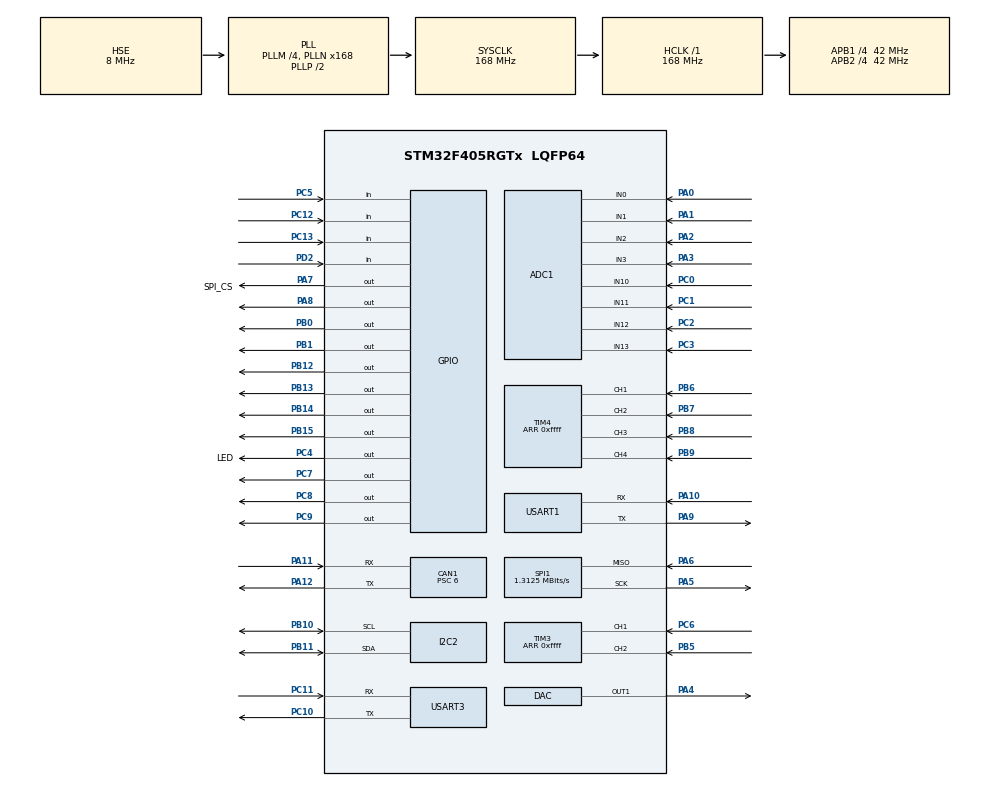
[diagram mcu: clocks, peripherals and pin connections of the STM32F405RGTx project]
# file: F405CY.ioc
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ADC1.Channel-0\#ChannelRegularConversion=ADC_CHANNEL_10
ADC1.Channel-1\#ChannelRegularConversion=ADC_CHANNEL_11
ADC1.Channel-2\#ChannelRegularConversion=ADC_CHANNEL_12
ADC1.Channel-3\#ChannelRegularConversion=ADC_CHANNEL_13
ADC1.Channel-4\#ChannelRegularConversion=ADC_CHANNEL_0
ADC1.Channel-5\#ChannelRegularConversion=ADC_CHANNEL_1
ADC1.Channel-6\#ChannelRegularConversion=ADC_CHANNEL_2
ADC1.Channel-7\#ChannelRegularConversion=ADC_CHANNEL_3
ADC1.DMAContinuousRequests=ENABLE
ADC1.ExternalTrigConv=ADC_EXTERNALTRIGCONV_T2_TRGO
ADC1.NbrOfConversion=8
ADC1.NbrOfConversionFlag=1
ADC1.Rank-0\#ChannelRegularConversion=1
ADC1.Rank-1\#ChannelRegularConversion=2
ADC1.Rank-2\#ChannelRegularConversion=3
ADC1.Rank-3\#ChannelRegularConversion=4
ADC1.Rank-4\#ChannelRegularConversion=5
ADC1.Rank-5\#ChannelRegularConversion=6
ADC1.Rank-6\#ChannelRegularConversion=7
ADC1.Rank-7\#ChannelRegularConversion=8
ADC1.SamplingTime-0\#ChannelRegularConversion=ADC_SAMPLETIME_3CYCLES
ADC1.SamplingTime-1\#ChannelRegularConversion=ADC_SAMPLETIME_3CYCLES
ADC1.SamplingTime-2\#ChannelRegularConversion=ADC_SAMPLETIME_3CYCLES
ADC1.SamplingTime-3\#ChannelRegularConversion=ADC_SAMPLETIME_3CYCLES
ADC1.SamplingTime-4\#ChannelRegularConversion=ADC_SAMPLETIME_3CYCLES
ADC1.SamplingTime-5\#ChannelRegularConversion=ADC_SAMPLETIME_3CYCLES
ADC1.SamplingTime-6\#ChannelRegularConversion=ADC_SAMPLETIME_3CYCLES
ADC1.SamplingTime-7\#ChannelRegularConversion=ADC_SAMPLETIME_3CYCLES
ADC1.ScanConvMode=ENABLE
ADC1.master=1
CAN1.BS1=CAN_BS1_7TQ
CAN1.BS2=CAN_BS2_6TQ
CAN1.CalculateTimeQuantum=142.85714285714286
CAN1.Prescaler=6
Dma.ADC1.2.Direction=DMA_PERIPH_TO_MEMORY
Dma.ADC1.2.FIFOMode=DMA_FIFOMODE_DISABLE
Dma.ADC1.2.Instance=DMA2_Stream0
Dma.ADC1.2.MemDataAlignment=DMA_MDATAALIGN_HALFWORD
Dma.ADC1.2.MemInc=DMA_MINC_ENABLE
Dma.ADC1.2.Mode=DMA_CIRCULAR
Dma.ADC1.2.PeriphDataAlignment=DMA_PDATAALIGN_HALFWORD
Dma.ADC1.2.PeriphInc=DMA_PINC_DISABLE
Dma.ADC1.2.Priority=DMA_PRIORITY_LOW
Dma.MEMTOMEM.3.Direction=DMA_MEMORY_TO_MEMORY
Dma.MEMTOMEM.3.FIFOMode=DMA_FIFOMODE_ENABLE
Dma.MEMTOMEM.3.FIFOThreshold=DMA_FIFO_THRESHOLD_FULL
Dma.MEMTOMEM.3.Instance=DMA2_Stream1
Dma.MEMTOMEM.3.MemBurst=DMA_MBURST_INC4
Dma.MEMTOMEM.3.MemDataAlignment=DMA_MDATAALIGN_HALFWORD
Dma.MEMTOMEM.3.MemInc=DMA_MINC_ENABLE
Dma.MEMTOMEM.3.Mode=DMA_NORMAL
Dma.MEMTOMEM.3.PeriphBurst=DMA_PBURST_INC4
Dma.MEMTOMEM.3.PeriphDataAlignment=DMA_PDATAALIGN_HALFWORD
Dma.MEMTOMEM.3.PeriphInc=DMA_PINC_ENABLE
Dma.MEMTOMEM.3.Priority=DMA_PRIORITY_LOW
Dma.Request0=USART1_RX
Dma.Request1=USART3_RX
Dma.Request2=ADC1
Dma.Request3=MEMTOMEM
Dma.USART1_RX.0.Direction=DMA_PERIPH_TO_MEMORY
Dma.USART1_RX.0.FIFOMode=DMA_FIFOMODE_DISABLE
Dma.USART1_RX.0.Instance=DMA2_Stream2
Dma.USART1_RX.0.MemDataAlignment=DMA_MDATAALIGN_BYTE
Dma.USART1_RX.0.MemInc=DMA_MINC_ENABLE
Dma.USART1_RX.0.Mode=DMA_NORMAL
Dma.USART1_RX.0.PeriphDataAlignment=DMA_PDATAALIGN_BYTE
Dma.USART1_RX.0.PeriphInc=DMA_PINC_DISABLE
Dma.USART1_RX.0.Priority=DMA_PRIORITY_LOW
Dma.USART3_RX.1.Direction=DMA_PERIPH_TO_MEMORY
Dma.USART3_RX.1.FIFOMode=DMA_FIFOMODE_DISABLE
Dma.USART3_RX.1.Instance=DMA1_Stream1
Dma.USART3_RX.1.MemDataAlignment=DMA_MDATAALIGN_BYTE
Dma.USART3_RX.1.MemInc=DMA_MINC_ENABLE
Dma.USART3_RX.1.Mode=DMA_NORMAL
Dma.USART3_RX.1.PeriphDataAlignment=DMA_PDATAALIGN_BYTE
Dma.USART3_RX.1.PeriphInc=DMA_PINC_DISABLE
Dma.USART3_RX.1.Priority=DMA_PRIORITY_LOW
FREERTOS.Queues01=canMsgQueue,16,CAN_MSG,0,Dynamic,NULL,NULL
FREERTOS.Tasks01=defaultTask,24,512,StartDefaultTask,As weak,NULL,Static,defaultTaskBuffer,defaultTaskControlBlock;usart1Task,8,512,StartUsart1Task,As weak,NULL,Static,usart1TaskBuffer,usart1TaskControlBlock;usart3Task,8,512,StartUsart3Task,As weak,NULL,Static,usart3TaskBuffer,usart3TaskControlBlock;adcTask,8,512,StartAdcTask,As weak,NULL,Static,adcTaskBuffer,adcTaskControlBlock;can1Task,8,512,StartCan1Task,As weak,NULL,Static,can1TaskBuffer,can1TaskControlBlock
I2C2.DutyCycle=I2C_DUTYCYCLE_16_9
I2C2.I2C_Mode=I2C_Fast
Mcu.Family=STM32F4
Mcu.Name=STM32F405RGTx
Mcu.Package=LQFP64
NVIC.CAN1_RX0_IRQn=true\:5\:0\:false\:false\:true\:true\:true\:true
NVIC.CAN1_RX1_IRQn=true\:5\:0\:false\:false\:true\:true\:true\:true
NVIC.DMA1_Stream1_IRQn=true\:5\:0\:false\:false\:true\:true\:false\:true
NVIC.DMA2_Stream0_IRQn=true\:5\:0\:false\:false\:true\:true\:false\:true
NVIC.DMA2_Stream1_IRQn=true\:5\:0\:false\:false\:true\:true\:true\:true
NVIC.DMA2_Stream2_IRQn=true\:5\:0\:false\:false\:true\:true\:false\:true
NVIC.PriorityGroup=NVIC_PRIORITYGROUP_4
NVIC.TIM1_UP_TIM10_IRQn=true\:0\:0\:false\:false\:true\:false\:false\:true
NVIC.TIM3_IRQn=true\:5\:0\:false\:false\:true\:true\:true\:true
NVIC.TIM4_IRQn=true\:5\:0\:false\:false\:true\:true\:true\:true
NVIC.TIM8_TRG_COM_TIM14_IRQn=true\:5\:0\:false\:false\:true\:true\:true\:true
NVIC.TimeBase=TIM1_UP_TIM10_IRQn
NVIC.TimeBaseIP=TIM1
NVIC.USART1_IRQn=true\:5\:0\:false\:false\:true\:true\:true\:true
NVIC.USART3_IRQn=true\:5\:0\:false\:false\:true\:true\:true\:true
PA0-WKUP.Signal=ADCx_IN0
PA1.Signal=ADCx_IN1
PA10.Mode=Asynchronous
PA10.Signal=USART1_RX
PA11.Mode=Master
PA11.Signal=CAN1_RX
PA12.Mode=Master
PA12.Signal=CAN1_TX
PA13.Mode=JTAG_5_pins
PA13.Signal=SYS_JTMS-SWDIO
PA14.Mode=JTAG_5_pins
PA14.Signal=SYS_JTCK-SWCLK
PA15.Mode=JTAG_5_pins
PA15.Signal=SYS_JTDI
PA2.Signal=ADCx_IN2
PA3.Signal=ADCx_IN3
PA4.Signal=COMP_DAC1_group
PA5.Mode=RX_Only_Simplex_Unidirect_Master
PA5.Signal=SPI1_SCK
PA6.Mode=RX_Only_Simplex_Unidirect_Master
PA6.Signal=SPI1_MISO
PA7.GPIO_Label=SPI_CS
PA7.PinState=GPIO_PIN_SET
PA7.Signal=GPIO_Output
PA8.Signal=GPIO_Output
PA9.Mode=Asynchronous
PA9.Signal=USART1_TX
PB0.Signal=GPIO_Output
PB1.Signal=GPIO_Output
PB10.Mode=I2C
PB10.Signal=I2C2_SCL
PB11.Mode=I2C
PB11.Signal=I2C2_SDA
PB12.GPIO_Speed=GPIO_SPEED_FREQ_HIGH
PB12.Signal=GPIO_Output
PB13.GPIO_Speed=GPIO_SPEED_FREQ_HIGH
PB13.Signal=GPIO_Output
PB14.GPIO_Speed=GPIO_SPEED_FREQ_HIGH
PB14.Signal=GPIO_Output
PB15.GPIO_Speed=GPIO_SPEED_FREQ_HIGH
PB15.Signal=GPIO_Output
PB3.Mode=JTAG_5_pins
PB3.Signal=SYS_JTDO-SWO
PB4.Mode=JTAG_5_pins
PB4.Signal=SYS_JTRST
PB5.GPIO_PuPd=GPIO_PULLUP
PB5.Signal=S_TIM3_CH2
PB6.GPIO_PuPd=GPIO_PULLUP
PB6.Signal=S_TIM4_CH1
PB7.GPIO_PuPd=GPIO_PULLUP
PB7.Signal=S_TIM4_CH2
PB8.GPIO_PuPd=GPIO_PULLUP
PB8.Signal=S_TIM4_CH3
PB9.GPIO_PuPd=GPIO_PULLUP
PB9.Signal=S_TIM4_CH4
PC0.Signal=ADCx_IN10
PC1.Signal=ADCx_IN11
PC10.Mode=Asynchronous
PC10.Signal=USART3_TX
PC11.Mode=Asynchronous
PC11.Signal=USART3_RX
PC12.GPIO_PuPd=GPIO_PULLUP
PC12.Signal=GPIO_Input
PC13-ANTI_TAMP.GPIO_PuPd=GPIO_PULLUP
PC13-ANTI_TAMP.Signal=GPIO_Input
PC14-OSC32_IN.Mode=LSE-External-Oscillator
PC14-OSC32_IN.Signal=RCC_OSC32_IN
PC15-OSC32_OUT.Mode=LSE-External-Oscillator
PC15-OSC32_OUT.Signal=RCC_OSC32_OUT
PC2.Signal=ADCx_IN12
PC3.Signal=ADCx_IN13
PC4.GPIO_Label=LED
PC4.GPIO_Speed=GPIO_SPEED_FREQ_HIGH
PC4.Signal=GPIO_Output
PC5.GPIO_PuPd=GPIO_PULLUP
PC5.Signal=GPIO_Input
PC6.GPIO_PuPd=GPIO_PULLUP
PC6.Signal=S_TIM3_CH1
PC7.GPIO_Speed=GPIO_SPEED_FREQ_HIGH
PC7.Signal=GPIO_Output
PC8.GPIO_Speed=GPIO_SPEED_FREQ_HIGH
PC8.Signal=GPIO_Output
PC9.GPIO_Speed=GPIO_SPEED_FREQ_HIGH
PC9.PinState=GPIO_PIN_RESET
PC9.Signal=GPIO_Output
PD2.GPIO_PuPd=GPIO_PULLUP
PD2.Signal=GPIO_Input
PH0-OSC_IN.Mode=HSE-External-Oscillator
PH0-OSC_IN.Signal=RCC_OSC_IN
PH1-OSC_OUT.Mode=HSE-External-Oscillator
PH1-OSC_OUT.Signal=RCC_OSC_OUT
ProjectManager.HeapSize=0x200
ProjectManager.StackSize=0x400
ProjectManager.TargetToolchain=STM32CubeIDE
RCC.48MHZClocksFreq_Value=84000000
RCC.AHBFreq_Value=168000000
RCC.APB1CLKDivider=RCC_HCLK_DIV4
RCC.APB1Freq_Value=42000000
RCC.APB1TimFreq_Value=84000000
RCC.APB2CLKDivider=RCC_HCLK_DIV4
RCC.APB2Freq_Value=42000000
RCC.APB2TimFreq_Value=84000000
RCC.CortexFreq_Value=168000000
RCC.HCLKFreq_Value=168000000
RCC.HSE_VALUE=8000000
RCC.HSI_VALUE=16000000
RCC.PLLM=4
RCC.PLLN=168
RCC.PLLSourceVirtual=RCC_PLLSOURCE_HSE
RCC.SYSCLKFreq_VALUE=168000000
RCC.SYSCLKSource=RCC_SYSCLKSOURCE_PLLCLK
RCC.VCOOutputFreq_Value=336000000
SH.ADCx_IN0.0=ADC1_IN0,IN0
SH.ADCx_IN1.0=ADC1_IN1,IN1
SH.ADCx_IN10.0=ADC1_IN10,IN10
SH.ADCx_IN11.0=ADC1_IN11,IN11
SH.ADCx_IN12.0=ADC1_IN12,IN12
SH.ADCx_IN13.0=ADC1_IN13,IN13
SH.ADCx_IN2.0=ADC1_IN2,IN2
SH.ADCx_IN3.0=ADC1_IN3,IN3
SH.COMP_DAC1_group.0=DAC_OUT1,DAC_OUT1
SH.S_TIM3_CH1.0=TIM3_CH1,Input_Capture1_from_TI1
SH.S_TIM3_CH2.0=TIM3_CH2,Input_Capture2_from_TI2
SH.S_TIM4_CH1.0=TIM4_CH1,Input_Capture1_from_TI1
SH.S_TIM4_CH2.0=TIM4_CH2,Input_Capture2_from_TI2
SH.S_TIM4_CH3.0=TIM4_CH3,Input_Capture3_from_TI3
SH.S_TIM4_CH4.0=TIM4_CH4,Input_Capture4_from_TI4
SPI1.BaudRatePrescaler=SPI_BAUDRATEPRESCALER_32
SPI1.CalculateBaudRate=1.3125 MBits/s
SPI1.DataSize=SPI_DATASIZE_16BIT
SPI1.Direction=SPI_DIRECTION_2LINES_RXONLY
SPI1.Mode=SPI_MODE_MASTER
SPI1.VirtualType=VM_MASTER
TIM14.AutoReloadPreload=TIM_AUTORELOAD_PRELOAD_ENABLE
TIM14.Period=999
TIM14.Prescaler=41
TIM2.AutoReloadPreload=TIM_AUTORELOAD_PRELOAD_ENABLE
TIM2.Period=524
TIM2.Prescaler=49
TIM2.TIM_MasterOutputTrigger=TIM_TRGO_UPDATE
TIM3.AutoReloadPreload=TIM_AUTORELOAD_PRELOAD_ENABLE
TIM3.Channel-Input_Capture1_from_TI1=TIM_CHANNEL_1
TIM3.Channel-Input_Capture2_from_TI2=TIM_CHANNEL_2
TIM3.ICPolarity_CH1=TIM_INPUTCHANNELPOLARITY_FALLING
TIM3.ICPolarity_CH2=TIM_INPUTCHANNELPOLARITY_FALLING
TIM3.Period=0xffff
TIM3.TIM_MasterOutputTrigger=TIM_TRGO_UPDATE
TIM4.AutoReloadPreload=TIM_AUTORELOAD_PRELOAD_ENABLE
TIM4.Channel-Input_Capture1_from_TI1=TIM_CHANNEL_1
TIM4.Channel-Input_Capture2_from_TI2=TIM_CHANNEL_2
TIM4.Channel-Input_Capture3_from_TI3=TIM_CHANNEL_3
TIM4.Channel-Input_Capture4_from_TI4=TIM_CHANNEL_4
TIM4.ICPolarity_CH1=TIM_INPUTCHANNELPOLARITY_FALLING
TIM4.ICPolarity_CH2=TIM_INPUTCHANNELPOLARITY_FALLING
TIM4.ICPolarity_CH3=TIM_INPUTCHANNELPOLARITY_FALLING
TIM4.ICPolarity_CH4=TIM_INPUTCHANNELPOLARITY_FALLING
TIM4.Period=0xffff
TIM4.TIM_MasterOutputTrigger=TIM_TRGO_UPDATE
USART1.VirtualMode=VM_ASYNC
USART3.VirtualMode=VM_ASYNC
VP_FREERTOS_VS_CMSIS_V2.Mode=CMSIS_V2
VP_SYS_VS_tim1.Mode=TIM1
VP_TIM14_VS_ClockSourceINT.Mode=Enable_Timer
VP_TIM2_VS_ClockSourceINT.Mode=Internal
board=custom

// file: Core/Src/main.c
/* USER CODE BEGIN Header */
/**
  ******************************************************************************
  * @file           : main.c
  * @brief          : Main program body
  ******************************************************************************
  * @attention
  *
  * <h2><center>&copy; Copyright (c) 2019 STMicroelectronics.
  * All rights reserved.</center></h2>
  *
  * This software component is licensed by ST under BSD 3-Clause license,
  * the "License"; You may not use this file except in compliance with the
  * License. You may obtain a copy of the License at:
  *                        opensource.org/licenses/BSD-3-Clause
  *
  ******************************************************************************
  */
/* USER CODE END Header */

#include "main.h"
#include "cmsis_os.h"
#include "adc.h"
#include "can.h"
#include "dac.h"
#include "dma.h"
#include "i2c.h"
#include "spi.h"
#include "tim.h"
#include "usart.h"
#include "gpio.h"

/* USER CODE BEGIN Includes */
#include "taskApp.h"

/* USER CODE END Includes */

void SystemClock_Config(void);
void MX_FREERTOS_Init(void);
/* USER CODE BEGIN PFP */
void init_led();
void InitMyApp();
void PorcKout();

/* USER CODE END PFP */

int main(void)
{

  /* MCU Configuration--------------------------------------------------------*/

  /* Reset of all peripherals, Initializes the Flash interface and the Systick. */
  HAL_Init();

  /* Configure the system clock */
  SystemClock_Config();

  /* Initialize all configured peripherals */
  MX_GPIO_Init();
  MX_DMA_Init();
  MX_USART1_UART_Init();
  MX_USART3_UART_Init();
  MX_ADC1_Init();
  MX_TIM2_Init();
  MX_CAN1_Init();
  MX_DAC_Init();
  MX_I2C2_Init();
  MX_SPI1_Init();
  MX_TIM3_Init();
  MX_TIM4_Init();
  MX_TIM14_Init();
  /* USER CODE BEGIN 2 */
  InitMyApp();
  /* USER CODE END 2 */
  /* Init scheduler */
  osKernelInitialize();

  /* Call init function for freertos objects (in freertos.c) */
  MX_FREERTOS_Init();

  /* Start scheduler */
  osKernelStart();

  /* We should never get here as control is now taken by the scheduler */

  /* Infinite loop */
  while (1)
  {

  }
}

void SystemClock_Config(void)
{
  RCC_OscInitTypeDef RCC_OscInitStruct = {0};
  RCC_ClkInitTypeDef RCC_ClkInitStruct = {0};

  /** Configure the main internal regulator output voltage
  */
  __HAL_RCC_PWR_CLK_ENABLE();
  __HAL_PWR_VOLTAGESCALING_CONFIG(PWR_REGULATOR_VOLTAGE_SCALE1);
  /** Initializes the CPU, AHB and APB busses clocks
  */
  RCC_OscInitStruct.OscillatorType = RCC_OSCILLATORTYPE_HSE;
  RCC_OscInitStruct.HSEState = RCC_HSE_ON;
  RCC_OscInitStruct.PLL.PLLState = RCC_PLL_ON;
  RCC_OscInitStruct.PLL.PLLSource = RCC_PLLSOURCE_HSE;
  RCC_OscInitStruct.PLL.PLLM = 4;
  RCC_OscInitStruct.PLL.PLLN = 168;
  RCC_OscInitStruct.PLL.PLLP = RCC_PLLP_DIV2;
  RCC_OscInitStruct.PLL.PLLQ = 4;
  if (HAL_RCC_OscConfig(&RCC_OscInitStruct) != HAL_OK)
  {
    Error_Handler();
  }
  /** Initializes the CPU, AHB and APB busses clocks
  */
  RCC_ClkInitStruct.ClockType = RCC_CLOCKTYPE_HCLK|RCC_CLOCKTYPE_SYSCLK
                              |RCC_CLOCKTYPE_PCLK1|RCC_CLOCKTYPE_PCLK2;
  RCC_ClkInitStruct.SYSCLKSource = RCC_SYSCLKSOURCE_PLLCLK;
  RCC_ClkInitStruct.AHBCLKDivider = RCC_SYSCLK_DIV1;
  RCC_ClkInitStruct.APB1CLKDivider = RCC_HCLK_DIV4;
  RCC_ClkInitStruct.APB2CLKDivider = RCC_HCLK_DIV4;

  if (HAL_RCC_ClockConfig(&RCC_ClkInitStruct, FLASH_LATENCY_5) != HAL_OK)
  {
    Error_Handler();
  }
}

void HAL_TIM_PeriodElapsedCallback(TIM_HandleTypeDef *htim)
{
  if (htim->Instance == TIM1) {
    HAL_IncTick();
  }
  /* USER CODE BEGIN Callback 1 */
  if(htim->Instance==TIM14)//2kHz
  {
	  ProcKout();
  }
  /* USER CODE END Callback 1 */
}

void Error_Handler(void)
{
}

/************************ (C) COPYRIGHT STMicroelectronics *****END OF FILE****/

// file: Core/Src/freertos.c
/* USER CODE BEGIN Header */
/**
  ******************************************************************************
  * File Name          : freertos.c
  * Description        : Code for freertos applications
  ******************************************************************************
  * @attention
  *
  * <h2><center>&copy; Copyright (c) 2019 STMicroelectronics.
  * All rights reserved.</center></h2>
  *
  * This software component is licensed by ST under Ultimate Liberty license
  * SLA0044, the "License"; You may not use this file except in compliance with
  * the License. You may obtain a copy of the License at:
  *                             www.st.com/SLA0044
  *
  ******************************************************************************
  */
/* USER CODE END Header */

#include "FreeRTOS.h"
#include "task.h"
#include "main.h"
#include "cmsis_os.h"

/* USER CODE BEGIN Includes */
#include "TaskApp.h"

/* USER CODE END Includes */

typedef StaticTask_t osStaticThreadDef_t;

/* Definitions for defaultTask */
osThreadId_t defaultTaskHandle;
uint32_t defaultTaskBuffer[ 512 ];
osStaticThreadDef_t defaultTaskControlBlock;
const osThreadAttr_t defaultTask_attributes = {
  .name = "defaultTask",
  .stack_mem = &defaultTaskBuffer[0],
  .stack_size = sizeof(defaultTaskBuffer),
  .cb_mem = &defaultTaskControlBlock,
  .cb_size = sizeof(defaultTaskControlBlock),
  .priority = (osPriority_t) osPriorityNormal,
};
/* Definitions for usart1Task */
osThreadId_t usart1TaskHandle;
uint32_t usart1TaskBuffer[ 512 ];
osStaticThreadDef_t usart1TaskControlBlock;
const osThreadAttr_t usart1Task_attributes = {
  .name = "usart1Task",
  .stack_mem = &usart1TaskBuffer[0],
  .stack_size = sizeof(usart1TaskBuffer),
  .cb_mem = &usart1TaskControlBlock,
  .cb_size = sizeof(usart1TaskControlBlock),
  .priority = (osPriority_t) osPriorityLow,
};
/* Definitions for usart3Task */
osThreadId_t usart3TaskHandle;
uint32_t usart3TaskBuffer[ 512 ];
osStaticThreadDef_t usart3TaskControlBlock;
const osThreadAttr_t usart3Task_attributes = {
  .name = "usart3Task",
  .stack_mem = &usart3TaskBuffer[0],
  .stack_size = sizeof(usart3TaskBuffer),
  .cb_mem = &usart3TaskControlBlock,
  .cb_size = sizeof(usart3TaskControlBlock),
  .priority = (osPriority_t) osPriorityLow,
};
/* Definitions for adcTask */
osThreadId_t adcTaskHandle;
uint32_t adcTaskBuffer[ 512 ];
osStaticThreadDef_t adcTaskControlBlock;
const osThreadAttr_t adcTask_attributes = {
  .name = "adcTask",
  .stack_mem = &adcTaskBuffer[0],
  .stack_size = sizeof(adcTaskBuffer),
  .cb_mem = &adcTaskControlBlock,
  .cb_size = sizeof(adcTaskControlBlock),
  .priority = (osPriority_t) osPriorityLow,
};
/* Definitions for can1Task */
osThreadId_t can1TaskHandle;
uint32_t can1TaskBuffer[ 512 ];
osStaticThreadDef_t can1TaskControlBlock;
const osThreadAttr_t can1Task_attributes = {
  .name = "can1Task",
  .stack_mem = &can1TaskBuffer[0],
  .stack_size = sizeof(can1TaskBuffer),
  .cb_mem = &can1TaskControlBlock,
  .cb_size = sizeof(can1TaskControlBlock),
  .priority = (osPriority_t) osPriorityLow,
};
/* Definitions for canMsgQueue */
osMessageQueueId_t canMsgQueueHandle;
const osMessageQueueAttr_t canMsgQueue_attributes = {
  .name = "canMsgQueue"
};

void StartDefaultTask(void *argument);
void StartUsart1Task(void *argument);
void StartUsart3Task(void *argument);
void StartAdcTask(void *argument);
void StartCan1Task(void *argument);

void MX_FREERTOS_Init(void); /* (MISRA C 2004 rule 8.1) */

void MX_FREERTOS_Init(void) {

  /* Create the queue(s) */
  /* creation of canMsgQueue */
  canMsgQueueHandle = osMessageQueueNew (16, sizeof(CAN_MSG), &canMsgQueue_attributes);

  /* Create the thread(s) */
  /* creation of defaultTask */
  defaultTaskHandle = osThreadNew(StartDefaultTask, NULL, &defaultTask_attributes);

  /* creation of usart1Task */
  usart1TaskHandle = osThreadNew(StartUsart1Task, NULL, &usart1Task_attributes);

  /* creation of usart3Task */
  usart3TaskHandle = osThreadNew(StartUsart3Task, NULL, &usart3Task_attributes);

  /* creation of adcTask */
  adcTaskHandle = osThreadNew(StartAdcTask, NULL, &adcTask_attributes);

  /* creation of can1Task */
  can1TaskHandle = osThreadNew(StartCan1Task, NULL, &can1Task_attributes);

}

__weak void StartDefaultTask(void *argument)
{
  for(;;)
  {
    osDelay(1);
  }
}

__weak void StartUsart1Task(void *argument)
{
  for(;;)
  {
    osDelay(1);
  }
}

__weak void StartUsart3Task(void *argument)
{
  for(;;)
  {
    osDelay(1);
  }
}

__weak void StartAdcTask(void *argument)
{
  for(;;)
  {
    osDelay(1);
  }
}

__weak void StartCan1Task(void *argument)
{
  for(;;)
  {
    osDelay(1);
  }
}

/************************ (C) COPYRIGHT STMicroelectronics *****END OF FILE****/
